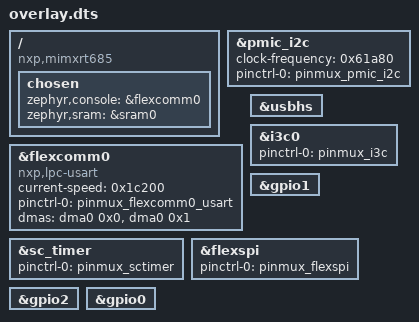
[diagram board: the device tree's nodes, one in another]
/ {
	compatible = "nxp,mimxrt685";
	chosen {
		zephyr,console = &flexcomm0;
		zephyr,sram = &sram0;
	};
};
&pmic_i2c{
	status = "okay";
	clock-frequency = < 0x61a80 >;
	#address-cells = < 0x1 >;
	#size-cells = < 0x0 >;
	pinctrl-0 = < &pinmux_pmic_i2c >;
	pinctrl-names = "default";
};
&flexcomm0{
	compatible = "nxp,lpc-usart";
	status = "okay";
	current-speed = < 0x1c200 >;
	pinctrl-0 = < &pinmux_flexcomm0_usart >;
	pinctrl-names = "default";
	dmas = < &dma0 0x0 >, < &dma0 0x1 >;
	dma-names = "rx", "tx";
};
&usbhs{
	status = "okay";
};
&i3c0{
	status = "okay";
	pinctrl-0 = < &pinmux_i3c >;
	pinctrl-names = "default";
};
&sc_timer{
	status = "okay";
	pinctrl-0 = < &pinmux_sctimer >;
	pinctrl-names = "default";
};
&gpio1{
	status = "okay";
};
&flexspi{
	status = "okay";
	pinctrl-0 = < &pinmux_flexspi >;
	pinctrl-names = "default";
};
&gpio2{
	status = "okay";
};
&gpio0{
	status = "okay";
};
